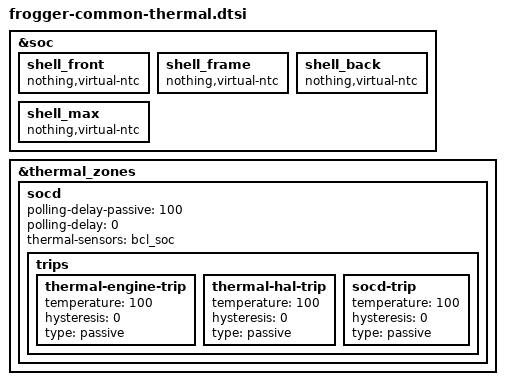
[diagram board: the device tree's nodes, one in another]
&soc {
	shell_front {
		compatible = "nothing,virtual-ntc";
	};

	shell_frame {
		compatible = "nothing,virtual-ntc";
	};

	shell_back {
		compatible = "nothing,virtual-ntc";
	};

	shell_max {
		compatible = "nothing,virtual-ntc";
	};
};

&thermal_zones {
	/*
	 * The nrpa_ntc cooling-maps that sat here have gone with the zone itself;
	 * see frogger-common-pmic.dtsi. They duplicated the base sys-therm-5 maps
	 * exactly, and it was their &display_test_config* references that bound
	 * the base zone's maps to the wrong zone's trips.
	 */

	socd {
		polling-delay-passive = <100>;
		polling-delay = <0>;
		thermal-sensors = <&bcl_soc>;

		trips {
			thermal-engine-trip {
				temperature = <100>;
				hysteresis = <0>;
				type = "passive";
			};

			thermal-hal-trip {
				temperature = <100>;
				hysteresis = <0>;
				type = "passive";
			};

			socd-trip {
				temperature = <100>;
				hysteresis = <0>;
				type = "passive";
			};
		};
	};
};
